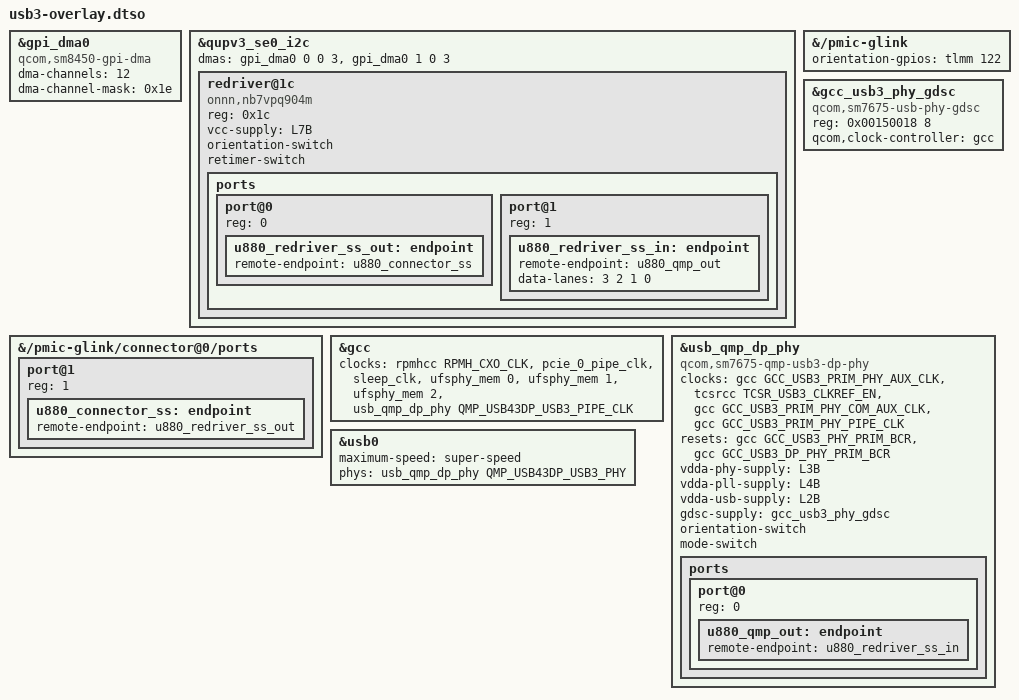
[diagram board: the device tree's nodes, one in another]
// SPDX-License-Identifier: GPL-2.0-only OR BSD-2-Clause
/*
 * U880 USB 3 (USB3=1, needs USB_MODE=otg): QMP USB3/DP combo PHY (uke sm7675 profile, tables equal to the U880 stock
 * qcom,qmp-phy-init-seq) behind the ON Semi NB7VPQ904M redriver (stock "onnn,redriver" @0x1c on QUP0 SE0 I2C).
 * SE0 is GPI-only (FIFO mode fails "Failed to get tx DMA ch"), so its GPI DMA engine is enabled as in the uke overlay.
 * Orientation: UCSI 1.x has none and altmode sends nothing for plain USB, so ucsi_glink reads gpio122 (PMIC CC_OUT)
 * -> connector -> redriver (typec switch) -> QMP (SW portselect). dwc3-qcom drops the bootloader pinctrl claim on it.
 * Applied after build-stock-disabled.sh section 6b, which creates /pmic-glink/connector@0.
 */
/dts-v1/;
/plugin/;

#include <dt-bindings/clock/qcom,gcc-cliffs.h>
#include <dt-bindings/gpio/gpio.h>
#include <dt-bindings/clock/qcom,rpmh.h>
#include <dt-bindings/clock/qcom,tcsrcc-pineapple.h>
#include <dt-bindings/phy/phy-qcom-qmp.h>

&gpi_dma0 {
	compatible = "qcom,sm8450-gpi-dma";
	#dma-cells = <3>;
	dma-channels = <12>;
	dma-channel-mask = <0x1e>;
	status = "okay";
};

&qupv3_se0_i2c {
	dmas = <&gpi_dma0 0 0 3>, <&gpi_dma0 1 0 3>;
	dma-names = "tx", "rx";
	#address-cells = <1>;
	#size-cells = <0>;

	redriver@1c {
		compatible = "onnn,nb7vpq904m";
		reg = <0x1c>;
		vcc-supply = <&L7B>;
		orientation-switch;
		retimer-switch;

		ports {
			#address-cells = <1>;
			#size-cells = <0>;
			port@0 { reg = <0>; u880_redriver_ss_out: endpoint { remote-endpoint = <&u880_connector_ss>; }; };
			port@1 {
				reg = <1>;
				/* stock lane-channel-swap */
				u880_redriver_ss_in: endpoint { remote-endpoint = <&u880_qmp_out>; data-lanes = <3 2 1 0>; };
			};
		};
	};
};

/* Plug orientation for UCSI 1.x firmware: PMIC CC_OUT on gpio122 (stock dwc3 "gpios"; 1 = reverse). */
&{/pmic-glink} {
	orientation-gpios = <&tlmm 122 GPIO_ACTIVE_HIGH>;
};

&{/pmic-glink/connector@0/ports} {
	port@1 { reg = <1>; u880_connector_ss: endpoint { remote-endpoint = <&u880_redriver_ss_out>; }; };
};

&gcc_usb3_phy_gdsc {
	compatible = "qcom,sm7675-usb-phy-gdsc";
	reg = <0x00150018 8>;
	qcom,clock-controller = <&gcc>;
	status = "okay";
};

&gcc {
	clocks = <&rpmhcc RPMH_CXO_CLK>, <&pcie_0_pipe_clk>, <&sleep_clk>,
		 <&ufsphy_mem 0>, <&ufsphy_mem 1>, <&ufsphy_mem 2>,
		 <&usb_qmp_dp_phy QMP_USB43DP_USB3_PIPE_CLK>;
};

&usb_qmp_dp_phy {
	compatible = "qcom,sm7675-qmp-usb3-dp-phy";
	#phy-cells = <1>;
	#clock-cells = <1>;
	clocks = <&gcc GCC_USB3_PRIM_PHY_AUX_CLK>,
		 <&tcsrcc TCSR_USB3_CLKREF_EN>,
		 <&gcc GCC_USB3_PRIM_PHY_COM_AUX_CLK>,
		 <&gcc GCC_USB3_PRIM_PHY_PIPE_CLK>;
	clock-names = "aux", "ref", "com_aux", "usb3_pipe";
	resets = <&gcc GCC_USB3_PHY_PRIM_BCR>, <&gcc GCC_USB3_DP_PHY_PRIM_BCR>;
	reset-names = "phy", "common";
	vdda-phy-supply = <&L3B>;
	vdda-pll-supply = <&L4B>;
	vdda-usb-supply = <&L2B>;
	gdsc-supply = <&gcc_usb3_phy_gdsc>;
	orientation-switch;
	mode-switch;
	status = "okay";

	ports {
		#address-cells = <1>;
		#size-cells = <0>;
		port@0 { reg = <0>; u880_qmp_out: endpoint { remote-endpoint = <&u880_redriver_ss_in>; }; };
	};
};

&usb0 {
	maximum-speed = "super-speed";
	phys = <&usb_qmp_dp_phy QMP_USB43DP_USB3_PHY>;
	phy-names = "usb3-phy";
};
